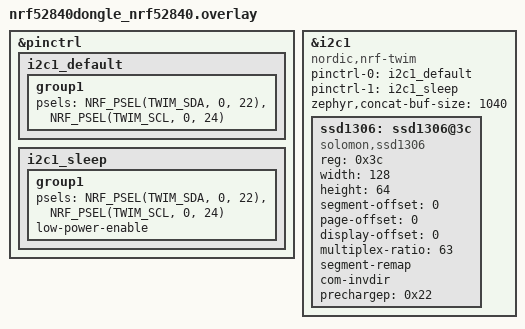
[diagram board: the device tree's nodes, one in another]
&pinctrl {
    i2c1_default: i2c1_default {
        group1 {
            psels = <NRF_PSEL(TWIM_SDA, 0, 22)>,
                    <NRF_PSEL(TWIM_SCL, 0, 24)>;
        };
    };

    i2c1_sleep: i2c1_sleep {
        group1 {
            psels = <NRF_PSEL(TWIM_SDA, 0, 22)>,
                    <NRF_PSEL(TWIM_SCL, 0, 24)>;
            low-power-enable;
        };
    };
};

&i2c1 {
    status = "okay";
    compatible = "nordic,nrf-twim";
    pinctrl-0 = <&i2c1_default>;
    pinctrl-1 = <&i2c1_sleep>;
    pinctrl-names = "default", "sleep";

    zephyr,concat-buf-size = <1040>;   /* >= 1 (control byte) + 1024 (128x64/8) */

    ssd1306: ssd1306@3c {
        compatible = "solomon,ssd1306";
        reg = <0x3c>;
        width = <128>;
        height = <64>;
        segment-offset = <0>;
        page-offset = <0>;
        display-offset = <0>;
        multiplex-ratio = <63>;
        segment-remap;
        com-invdir;
        prechargep = <0x22>;
    };
};
